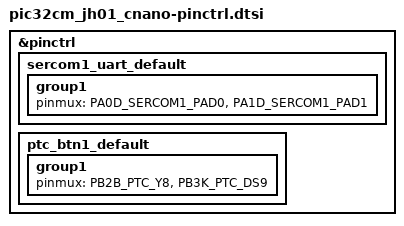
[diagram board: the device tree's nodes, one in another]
/*
 * Copyright (c) 2026 Microchip Technology Inc.
 *
 * SPDX-License-Identifier: Apache-2.0
 */

#include <dt-bindings/pic32c/pic32cm_jh/pic32cm_jh01/pic32cm5164jh01048-pinctrl.h>

&pinctrl {
	sercom1_uart_default: sercom1_uart_default {
		group1 {
			pinmux = <PA0D_SERCOM1_PAD0>,
				 <PA1D_SERCOM1_PAD1>;
		};
	};

	ptc_btn1_default: ptc_btn1_default {
		group1 {
			pinmux = <PB2B_PTC_Y8>,
				 <PB3K_PTC_DS9>;
		};
	};
};
